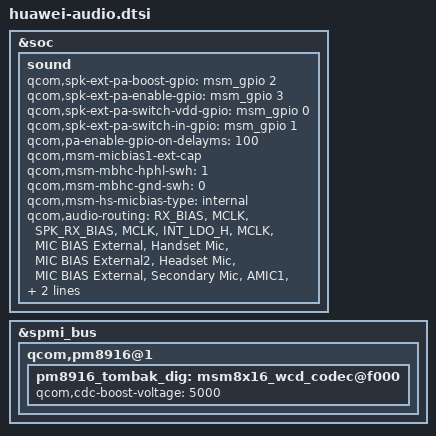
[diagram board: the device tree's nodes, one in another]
&soc {
    sound {
        qcom,spk-ext-pa-boost-gpio = <&msm_gpio 2 0>;
        qcom,spk-ext-pa-enable-gpio = <&msm_gpio 3 0>;
        qcom,spk-ext-pa-switch-vdd-gpio = <&msm_gpio 0 0>;
        qcom,spk-ext-pa-switch-in-gpio = <&msm_gpio 1 0>;
        qcom,pa-enable-gpio-on-delayms = <100>;

        qcom,msm-micbias1-ext-cap;
        qcom,msm-mbhc-hphl-swh = <1>;
		qcom,msm-mbhc-gnd-swh = <0>;
		qcom,msm-micbias1-ext-cap;
		qcom,msm-hs-micbias-type = "internal";
		qcom,audio-routing =
			"RX_BIAS", "MCLK",
			"SPK_RX_BIAS", "MCLK",
			"INT_LDO_H", "MCLK",
			"MIC BIAS External", "Handset Mic",
			"MIC BIAS External2", "Headset Mic",
			"MIC BIAS External", "Secondary Mic",
			"AMIC1", "MIC BIAS External",
			"AMIC2", "MIC BIAS External2",
			"AMIC3", "MIC BIAS External";
		pinctrl-names = "cdc_lines_act",
				"cdc_lines_sus";
    };
};

&spmi_bus {
        qcom,pm8916@1 {
                pm8916_tombak_dig: msm8x16_wcd_codec@f000{
                        qcom,cdc-boost-voltage = <5000>;
                };
        };
};
